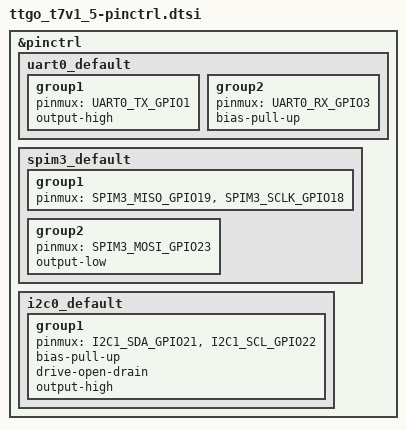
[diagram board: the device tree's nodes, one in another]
/*
 * Copyright 2024 Tobias Kässer <t.kaesser@gmail.com>
 *
 * SPDX-License-Identifier: Apache-2.0
 */

#include <zephyr/dt-bindings/pinctrl/esp-pinctrl-common.h>
#include <dt-bindings/pinctrl/esp32-pinctrl.h>
#include <zephyr/dt-bindings/pinctrl/esp32-gpio-sigmap.h>

&pinctrl {
	uart0_default: uart0_default {
		group1 {
			pinmux = <UART0_TX_GPIO1>;
			output-high;
		};

		group2 {
			pinmux = <UART0_RX_GPIO3>;
			bias-pull-up;
		};
	};

	spim3_default: spim3_default {
		group1 {
			pinmux = <SPIM3_MISO_GPIO19>,
				 <SPIM3_SCLK_GPIO18>;
		};

		/* GPIO5 is CS */
		group2 {
			pinmux = <SPIM3_MOSI_GPIO23>;
			output-low;
		};
	};

	i2c0_default: i2c0_default {
		group1 {
			pinmux = <I2C1_SDA_GPIO21>,
				 <I2C1_SCL_GPIO22>;
			bias-pull-up;
			drive-open-drain;
			output-high;
		};
	};
};
